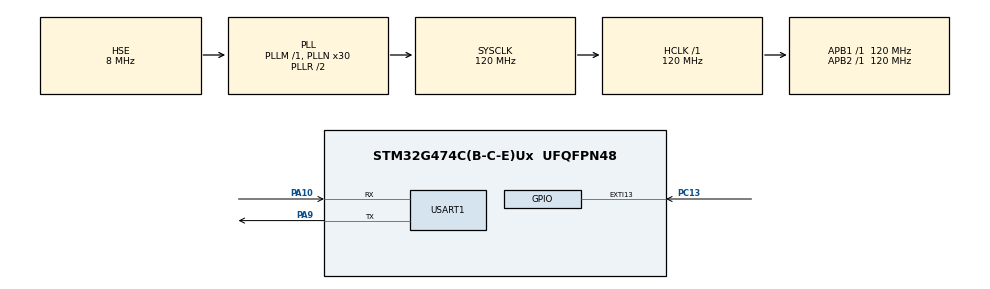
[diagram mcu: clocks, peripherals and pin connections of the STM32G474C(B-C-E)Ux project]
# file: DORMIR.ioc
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Mcu.Family=STM32G4
Mcu.Name=STM32G474C(B-C-E)Ux
Mcu.Package=UFQFPN48
NVIC.EXTI15_10_IRQn=true\:0\:0\:false\:false\:true\:true\:true\:true
NVIC.PriorityGroup=NVIC_PRIORITYGROUP_4
NVIC.RTC_WKUP_IRQn=true\:0\:0\:false\:false\:true\:true\:true\:true
PA10.Mode=Asynchronous
PA10.Signal=USART1_RX
PA9.Mode=Asynchronous
PA9.Signal=USART1_TX
PC13.GPIO_ModeDefaultEXTI=GPIO_MODE_IT_RISING
PC13.GPIO_PuPd=GPIO_PULLDOWN
PC13.Signal=GPXTI13
PC14-OSC32_IN.Mode=LSE-External-Oscillator
PC14-OSC32_IN.Signal=RCC_OSC32_IN
PC15-OSC32_OUT.Mode=LSE-External-Oscillator
PC15-OSC32_OUT.Signal=RCC_OSC32_OUT
PF0-OSC_IN.Mode=HSE-External-Oscillator
PF0-OSC_IN.Signal=RCC_OSC_IN
PF1-OSC_OUT.Mode=HSE-External-Oscillator
PF1-OSC_OUT.Signal=RCC_OSC_OUT
ProjectManager.HeapSize=0x200
ProjectManager.StackSize=0x400
ProjectManager.TargetToolchain=STM32CubeIDE
RCC.ADC12Freq_Value=120000000
RCC.ADC345Freq_Value=120000000
RCC.AHBFreq_Value=120000000
RCC.APB1Freq_Value=120000000
RCC.APB1TimFreq_Value=120000000
RCC.APB2Freq_Value=120000000
RCC.APB2TimFreq_Value=120000000
RCC.CortexFreq_Value=120000000
RCC.EXTERNAL_CLOCK_VALUE=12288000
RCC.HCLKFreq_Value=120000000
RCC.HSE_VALUE=8000000
RCC.HSI48_VALUE=48000000
RCC.HSI_VALUE=16000000
RCC.PLLN=30
RCC.PLLSourceVirtual=RCC_PLLSOURCE_HSE
RCC.SYSCLKFreq_VALUE=120000000
RCC.SYSCLKSource=RCC_SYSCLKSOURCE_PLLCLK
RCC.USBFreq_Value=120000000
RCC.VCOOutputFreq_Value=240000000
RTC.WakeUpClock-WakeUp=RTC_WAKEUPCLOCK_CK_SPRE_16BITS
USART1.VirtualMode-Asynchronous=VM_ASYNC
VP_RTC_VS_RTC_Activate.Mode=RTC_Enabled
VP_RTC_VS_RTC_Calendar.Mode=RTC_Calendar
VP_RTC_VS_RTC_WakeUp_intern.Mode=WakeUp
VP_SYS_VS_DBSignals.Mode=DisableDeadBatterySignals
board=custom

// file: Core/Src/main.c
/* USER CODE BEGIN Header */
/**
  ******************************************************************************
  * @file           : main.c
  * @brief          : Main program body
  ******************************************************************************
  * @attention
  *
  * Copyright (c) 2025 STMicroelectronics.
  * All rights reserved.
  *
  * This software is licensed under terms that can be found in the LICENSE file
  * in the root directory of this software component.
  * If no LICENSE file comes with this software, it is provided AS-IS.
  *
  ******************************************************************************
  */
/* USER CODE END Header */
#include "main.h"

/* USER CODE BEGIN Includes */
#include "uart.h"
/* USER CODE END Includes */

RTC_HandleTypeDef hrtc;

UART_HandleTypeDef huart1;

void SystemClock_Config(void);
static void MX_GPIO_Init(void);
static void MX_USART1_UART_Init(void);
static void MX_RTC_Init(void);

int main(void)
{

  /* MCU Configuration--------------------------------------------------------*/

  /* Reset of all peripherals, Initializes the Flash interface and the Systick. */
  HAL_Init();

  /* Configure the system clock */
  SystemClock_Config();

  /* Initialize all configured peripherals */
  MX_GPIO_Init();
  MX_USART1_UART_Init();
  MX_RTC_Init();
  /* USER CODE BEGIN 2 */
  uartx_write_text(&huart1, "INICIANDO\r\n");
  /* USER CODE END 2 */

  /* Infinite loop */
  /* USER CODE BEGIN WHILE */
  while (1)
  {

//LEVANTATE  AUTOMATICO CIERTO TIEMPO
	  if (HAL_RTCEx_SetWakeUpTimer_IT(&hrtc, 5, RTC_WAKEUPCLOCK_CK_SPRE_16BITS) != HAL_OK) {
	 	      Error_Handler();
	 	  }

	  //DORMIR
	  uartx_write_text(&huart1, "DURMIENDO\r\n");
	  //supende el contador de tick
	  	  HAL_SuspendTick();
	 	   //Habilita Salir con Interrupciones
	 	   HAL_PWR_EnableSleepOnExit();

	 	   //MODO SLEEP
	// HAL_PWR_EnterSLEEPMode(PWR_LOWPOWERREGULATOR_ON, PWR_STOPENTRY_WFI);

    //MODO STOP

  HAL_PWR_EnterSTOPMode(PWR_LOWPOWERREGULATOR_ON, PWR_STOPENTRY_WFI);

   //MODO STANDBY
  // HAL_PWR_EnterSTANDBYMode();

//

	//  OPERANDO
		uartx_write_text(&huart1, "OPERANDO\r\n");
		 HAL_Delay(6000);

    /* USER CODE END WHILE */

  }
}

void SystemClock_Config(void)
{
  RCC_OscInitTypeDef RCC_OscInitStruct = {0};
  RCC_ClkInitTypeDef RCC_ClkInitStruct = {0};

  /** Configure the main internal regulator output voltage
  */
  HAL_PWREx_ControlVoltageScaling(PWR_REGULATOR_VOLTAGE_SCALE1);

  /** Initializes the RCC Oscillators according to the specified parameters
  * in the RCC_OscInitTypeDef structure.
  */
  RCC_OscInitStruct.OscillatorType = RCC_OSCILLATORTYPE_LSI|RCC_OSCILLATORTYPE_HSE;
  RCC_OscInitStruct.HSEState = RCC_HSE_ON;
  RCC_OscInitStruct.LSIState = RCC_LSI_ON;
  RCC_OscInitStruct.PLL.PLLState = RCC_PLL_ON;
  RCC_OscInitStruct.PLL.PLLSource = RCC_PLLSOURCE_HSE;
  RCC_OscInitStruct.PLL.PLLM = RCC_PLLM_DIV1;
  RCC_OscInitStruct.PLL.PLLN = 30;
  RCC_OscInitStruct.PLL.PLLP = RCC_PLLP_DIV2;
  RCC_OscInitStruct.PLL.PLLQ = RCC_PLLQ_DIV2;
  RCC_OscInitStruct.PLL.PLLR = RCC_PLLR_DIV2;
  if (HAL_RCC_OscConfig(&RCC_OscInitStruct) != HAL_OK)
  {
    Error_Handler();
  }

  /** Initializes the CPU, AHB and APB buses clocks
  */
  RCC_ClkInitStruct.ClockType = RCC_CLOCKTYPE_HCLK|RCC_CLOCKTYPE_SYSCLK
                              |RCC_CLOCKTYPE_PCLK1|RCC_CLOCKTYPE_PCLK2;
  RCC_ClkInitStruct.SYSCLKSource = RCC_SYSCLKSOURCE_PLLCLK;
  RCC_ClkInitStruct.AHBCLKDivider = RCC_SYSCLK_DIV1;
  RCC_ClkInitStruct.APB1CLKDivider = RCC_HCLK_DIV1;
  RCC_ClkInitStruct.APB2CLKDivider = RCC_HCLK_DIV1;

  if (HAL_RCC_ClockConfig(&RCC_ClkInitStruct, FLASH_LATENCY_3) != HAL_OK)
  {
    Error_Handler();
  }
}

static void MX_RTC_Init(void)
{

  RTC_TimeTypeDef sTime = {0};
  RTC_DateTypeDef sDate = {0};

  /** Initialize RTC Only
  */
  hrtc.Instance = RTC;
  hrtc.Init.HourFormat = RTC_HOURFORMAT_24;
  hrtc.Init.AsynchPrediv = 127;
  hrtc.Init.SynchPrediv = 255;
  hrtc.Init.OutPut = RTC_OUTPUT_DISABLE;
  hrtc.Init.OutPutRemap = RTC_OUTPUT_REMAP_NONE;
  hrtc.Init.OutPutPolarity = RTC_OUTPUT_POLARITY_HIGH;
  hrtc.Init.OutPutType = RTC_OUTPUT_TYPE_OPENDRAIN;
  hrtc.Init.OutPutPullUp = RTC_OUTPUT_PULLUP_NONE;
  if (HAL_RTC_Init(&hrtc) != HAL_OK)
  {
    Error_Handler();
  }

  /** Initialize RTC and set the Time and Date
  */
  sTime.Hours = 0x0;
  sTime.Minutes = 0x0;
  sTime.Seconds = 0x0;
  sTime.SubSeconds = 0x0;
  sTime.DayLightSaving = RTC_DAYLIGHTSAVING_NONE;
  sTime.StoreOperation = RTC_STOREOPERATION_RESET;
  if (HAL_RTC_SetTime(&hrtc, &sTime, RTC_FORMAT_BCD) != HAL_OK)
  {
    Error_Handler();
  }
  sDate.WeekDay = RTC_WEEKDAY_MONDAY;
  sDate.Month = RTC_MONTH_JANUARY;
  sDate.Date = 0x1;
  sDate.Year = 0x0;

  if (HAL_RTC_SetDate(&hrtc, &sDate, RTC_FORMAT_BCD) != HAL_OK)
  {
    Error_Handler();
  }

  /** Enable the WakeUp
  */
  if (HAL_RTCEx_SetWakeUpTimer_IT(&hrtc, 0, RTC_WAKEUPCLOCK_CK_SPRE_16BITS) != HAL_OK)
  {
    Error_Handler();
  }

}

static void MX_USART1_UART_Init(void)
{

  huart1.Instance = USART1;
  huart1.Init.BaudRate = 115200;
  huart1.Init.WordLength = UART_WORDLENGTH_8B;
  huart1.Init.StopBits = UART_STOPBITS_1;
  huart1.Init.Parity = UART_PARITY_NONE;
  huart1.Init.Mode = UART_MODE_TX_RX;
  huart1.Init.HwFlowCtl = UART_HWCONTROL_NONE;
  huart1.Init.OverSampling = UART_OVERSAMPLING_16;
  huart1.Init.OneBitSampling = UART_ONE_BIT_SAMPLE_DISABLE;
  huart1.Init.ClockPrescaler = UART_PRESCALER_DIV1;
  huart1.AdvancedInit.AdvFeatureInit = UART_ADVFEATURE_NO_INIT;
  if (HAL_UART_Init(&huart1) != HAL_OK)
  {
    Error_Handler();
  }
  if (HAL_UARTEx_SetTxFifoThreshold(&huart1, UART_TXFIFO_THRESHOLD_1_8) != HAL_OK)
  {
    Error_Handler();
  }
  if (HAL_UARTEx_SetRxFifoThreshold(&huart1, UART_RXFIFO_THRESHOLD_1_8) != HAL_OK)
  {
    Error_Handler();
  }
  if (HAL_UARTEx_DisableFifoMode(&huart1) != HAL_OK)
  {
    Error_Handler();
  }

}

static void MX_GPIO_Init(void)
{
  GPIO_InitTypeDef GPIO_InitStruct = {0};

  /* GPIO Ports Clock Enable */
  __HAL_RCC_GPIOC_CLK_ENABLE();
  __HAL_RCC_GPIOF_CLK_ENABLE();
  __HAL_RCC_GPIOA_CLK_ENABLE();

  /*Configure GPIO pin : PC13 */
  GPIO_InitStruct.Pin = GPIO_PIN_13;
  GPIO_InitStruct.Mode = GPIO_MODE_IT_RISING;
  GPIO_InitStruct.Pull = GPIO_PULLDOWN;
  HAL_GPIO_Init(GPIOC, &GPIO_InitStruct);

  /* EXTI interrupt init*/
  HAL_NVIC_SetPriority(EXTI15_10_IRQn, 0, 0);
  HAL_NVIC_EnableIRQ(EXTI15_10_IRQn);

}

void Error_Handler(void)
{
  __disable_irq();
  while (1)
  {
  }
}
